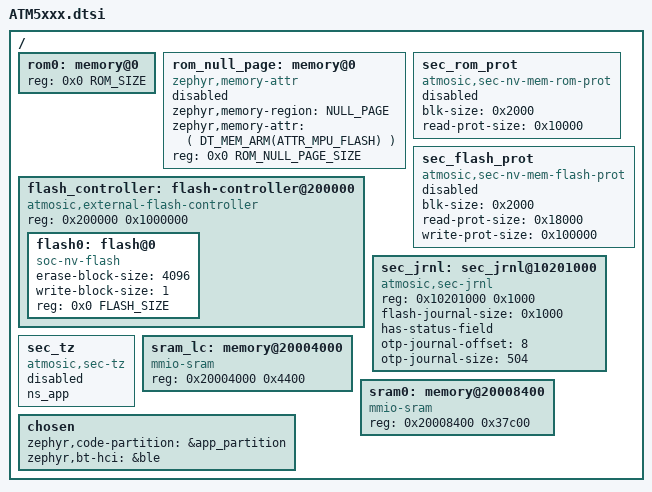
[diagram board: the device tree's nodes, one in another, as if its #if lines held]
/*
 * Copyright (c) 2024-2026 Atmosic
 *
 * SPDX-License-Identifier: LicenseRef-Atmosic
 */

#include <arm/atmosic/ATM5.dtsi>
#include <zephyr/dt-bindings/memory-attr/memory-attr.h>
#include <zephyr/dt-bindings/memory-attr/memory-attr-arm.h>

#ifndef ROM_SIZE
#define ROM_SIZE 0x80000
#endif

#ifndef FLASH_SIZE
#define FLASH_SIZE 0x200000
#endif

#ifndef ATM_NS_APP
#ifndef ROM_NULL_PAGE_SIZE
#define ROM_NULL_PAGE_SIZE 4096
#endif

#ifndef ATM_NO_TZ
#define SRAM_SIZE 0x4000
#if ATM_SEC_FAULT_STORAGE
#define ATM_SEC_FAULT_STORAGE_NODE 30003FE0
#define ATM_SEC_FAULT_STORAGE_SIZE 32
#define ATM_SEC_FAULT_STORAGE_ADDR (0x30000000 + SRAM_SIZE - ATM_SEC_FAULT_STORAGE_SIZE)

#define CAT(a, b) a##b
#define CAT_HEX(x) CAT(0x, x)
#if ATM_SEC_FAULT_STORAGE_ADDR != CAT_HEX(ATM_SEC_FAULT_STORAGE_NODE)
#error "ATM_SEC_FAULT_STORAGE_ADDR must equal ATM_SEC_FAULT_STORAGE_NODE"
#endif
#endif // ATM_SEC_FAULT_STORAGE
#endif // ATM_NO_TZ
#endif // ATM_NS_APP

/ {

#ifdef ATM_NS_APP
	rom0: memory@0 {
		device_type = "memory";
		reg = <0x0 ROM_SIZE>;
	};
#else
	rom0: memory@10000000 {
		device_type = "memory";
		reg = <0x10000000 ROM_SIZE>;
	};
#endif

#ifndef ATM_NS_APP
	// define the area for the MPU to catch NULL pointers
	// use the lower half of the boot-rom
	// When ATM_MPC_NULL_POINTER_DETECTION is defined, MPC is used instead
	// of MPU for NULL pointer detection, so this node should be disabled.
	rom_null_page: memory@0 {
		compatible = "zephyr,memory-attr","zephyr,memory-region";
		zephyr,memory-region = "NULL_PAGE";
		zephyr,memory-attr = <( DT_MEM_ARM(ATTR_MPU_FLASH) )>;
		device_type = "memory";
		reg = <0x0 ROM_NULL_PAGE_SIZE>;
#ifdef ATM_MPC_NULL_POINTER_DETECTION
		status = "disabled";
#endif
	};
#endif

#ifdef ATM_NS_APP
	flash_controller: flash-controller@200000 {
#else
	flash_controller: flash-controller@10200000 {
#endif
		compatible = "atmosic,external-flash-controller";

		#address-cells = <1>;
		#size-cells = <1>;

#ifdef ATM_NS_APP
		reg = <0x200000 0x1000000>;
		ranges = <0x0 0x200000 0x1000000>;
#else
		reg = <0x10200000 0x1000000>;
		ranges = <0x0 0x10200000 0x1000000>;
#endif

		flash0: flash@0 {
			compatible = "soc-nv-flash";
			erase-block-size = <4096>;
			write-block-size = <1>;
			reg = <0x0 FLASH_SIZE>;
		};
	};

	sec_rom_prot: sec_rom_prot {
		compatible = "atmosic,sec-nv-mem-rom-prot";
		blk-size = <0x2000>;
		read-prot-size = <0x10000>;
#ifdef ATM_NS_APP
		status = "disabled";
#endif
	};

	sec_flash_prot: sec_flash_prot {
		compatible = "atmosic,sec-nv-mem-flash-prot";
		blk-size = <0x2000>;
		read-prot-size = <0x18000>;
		write-prot-size= <0x100000>;
#ifdef ATM_NS_APP
		status = "disabled";
#endif
	};

	sec_jrnl: sec_jrnl@10201000 {
		compatible = "atmosic,sec-jrnl";

		#address-cells = <1>;
		#size-cells = <1>;

		reg = <0x10201000 0x1000>;

		flash-journal-size = <0x1000>;
		has-status-field;
		otp-journal-offset = <8>;
		otp-journal-size = <504>;
	};

#ifdef ATM_NS_APP

	sec_tz: sec_tz {
		compatible = "atmosic,sec-tz";
		ns_app;
		status = "disabled";
	};

	sram_lc: memory@20004000 {
		device_type = "memory";
		compatible = "mmio-sram";
		reg = <0x20004000 0x4400>;
	};

	sram0: memory@20008400 {
		device_type = "memory";
		compatible = "mmio-sram";
		reg = <0x20008400 0x37c00>;
	};

#else
	otp: otp {
		compatible = "atmosic,otp";
		otp-size = <504>;
	};

	sec_debug: sec_debug {
		compatible = "atmosic,sec-debug";
	};

	sec_sideload_keys: sec_sideload_keys@10200000 {
		compatible = "atmosic,sec-sideload-keys";

		#address-cells = <1>;
		#size-cells = <1>;

		reg = <0x10200000 0x1000>;
	};

	sec_tz: sec_tz {
		compatible = "atmosic,sec-tz";
#if defined(ATM_NO_TZ)
		status = "disabled";
#else
		allow_nsc_in_ram;
#endif
	};

#if ATM_SEC_FAULT_STORAGE
	sram0: memory@30000000 {
		device_type = "memory";
		compatible = "mmio-sram";
		reg = <0x30000000 (SRAM_SIZE - ATM_SEC_FAULT_STORAGE_SIZE)>;
	};
	spe_fault_storage: spe_fault_storage@ATM_SEC_FAULT_STORAGE_NODE {
		device_type = "memory";
		compatible = "atmosic,spe-fault-storage";
		reg = <ATM_SEC_FAULT_STORAGE_ADDR ATM_SEC_FAULT_STORAGE_SIZE>;
	};
#elif defined(ATM_NO_TZ)
	sram_lc: memory@30004000 {
		device_type = "memory";
		compatible = "mmio-sram";
		reg = <0x30004000 0x4400>;
	};
	sram0: memory@30000000 {
		device_type = "memory";
		compatible = "mmio-sram";
		reg = <0x30008400 0x37c00>;
	};
#else
	sram0: memory@30000000 {
		device_type = "memory";
		compatible = "mmio-sram";
		reg = <0x30000000 SRAM_SIZE>;
	};
#endif
#endif // ATM_NS_APP
};

#include "ATM5xxx_partitions.dtsi"

/ {
	chosen {
#if defined(ATM_NO_TZ)
		zephyr,code-partition = &app_partition;
#elif defined(ATM_NS_APP)
		zephyr,code-partition = &nspe_partition;
#else
		zephyr,code-partition = &spe_partition;
#endif
#ifdef ATM_DTS_USER_APP
		zephyr,bt-hci = &ble;
#endif
	};
};
